VERSION "1.0"

NS_ :

BS_:

BU_:
PCM1 FOO
VAL_TABLE_ Table3 16 "16" 7 "7" 2 "2" 0 "0" ;
VAL_TABLE_ Table2  ;
VAL_TABLE_ Table1 1 "One" 0 "Zero" ;

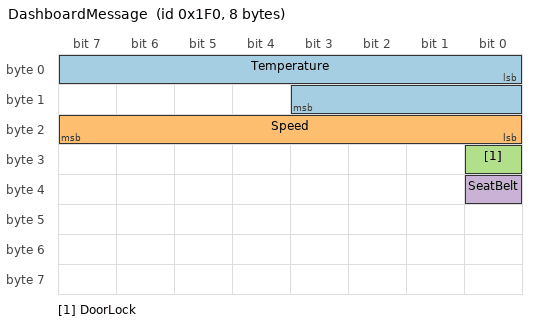
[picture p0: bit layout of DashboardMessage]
BO_ 496 DashboardMessage: 8 Dashboard
 SG_ Temperature : 0|12@1- (1,-10) [-10|200] "degC"  PCM1,FOO
 SG_ Speed : 16|8@1+ (1,0) [0|250] "km/h" Vector__XXX
 SG_ DoorLock : 24|1@1+ (1,0) [0|0] "-" Vector__XXX
 SG_ SeatBelt : 32|1@1+ (1,0) [0|0] "-" Vector__XXX

BO_ 444 EmergencyMessage: 4 Vector__XXX
 SG_ CrashStat : 0|1@1+ (1,0) [0|0] "" Vector__XXX
 SG_ AirbagStat : 8|1@1+ (1,0) [0|0] "" Vector__XXX

CM_ BO_ 496 "Dashboard message used for Basic details of Vehicle.";
CM_ BO_ 444 "Emergency Message used for Information About Emergency Situation";

VAL_ 496 DoorLock 0 "Door_Open" 1 "Door_Lock" ;
VAL_ 444 CrashStat 1 "Crash_Detect" 0 "Vehicle_Safe";
VAL_ 444 AirbagStat 1 "Airbag_Released" 0 "Fine_Airbag";
